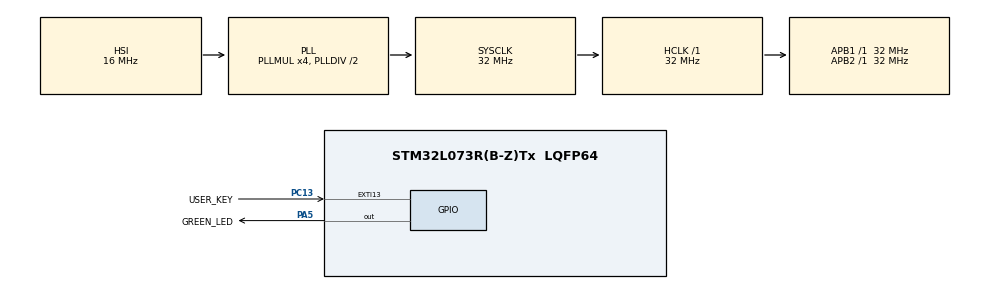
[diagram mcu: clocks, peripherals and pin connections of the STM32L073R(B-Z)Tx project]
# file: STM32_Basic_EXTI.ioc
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Mcu.Family=STM32L0
Mcu.Name=STM32L073R(B-Z)Tx
Mcu.Package=LQFP64
NVIC.EXTI4_15_IRQn=true\:1\:0\:true\:false\:true\:true
PA13.Mode=Serial_Wire
PA13.Signal=SYS_SWDIO
PA14.Mode=Serial_Wire
PA14.Signal=SYS_SWCLK
PA5.GPIO_Label=GREEN_LED
PA5.GPIO_Speed=GPIO_SPEED_FREQ_MEDIUM
PA5.Signal=GPIO_Output
PC13.GPIO_Label=USER_KEY
PC13.GPIO_ModeDefaultEXTI=GPIO_MODE_IT_FALLING
PC13.Signal=GPXTI13
ProjectManager.HeapSize=0x200
ProjectManager.StackSize=0x400
ProjectManager.TargetToolchain=TrueSTUDIO
RCC.AHBFreq_Value=32000000
RCC.APB1Freq_Value=32000000
RCC.APB1TimFreq_Value=32000000
RCC.APB2Freq_Value=32000000
RCC.APB2TimFreq_Value=32000000
RCC.HCLKFreq_Value=32000000
RCC.HSE_VALUE=8000000
RCC.HSI16_VALUE=16000000
RCC.HSI48_VALUE=48000000
RCC.HSI_VALUE=16000000
RCC.LSE_VALUE=32768
RCC.MSI_VALUE=2097000
RCC.PLLMUL=RCC_PLLMUL_4
RCC.SYSCLKFreq_VALUE=32000000
RCC.SYSCLKSource=RCC_SYSCLKSOURCE_PLLCLK
RCC.VCOOutputFreq_Value=64000000
board=custom

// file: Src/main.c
/* USER CODE BEGIN Header */
/**
  ******************************************************************************
  * @file           : main.c
  * @brief          : Main program body
  ******************************************************************************
  ** This notice applies to any and all portions of this file
  * that are not between comment pairs USER CODE BEGIN and
  * USER CODE END. Other portions of this file, whether
  * inserted by the user or by software development tools
  * are owned by their respective copyright owners.
  *
  * COPYRIGHT(c) 2019 STMicroelectronics
  *
  * Redistribution and use in source and binary forms, with or without modification,
  * are permitted provided that the following conditions are met:
  *   1. Redistributions of source code must retain the above copyright notice,
  *      this list of conditions and the following disclaimer.
  *   2. Redistributions in binary form must reproduce the above copyright notice,
  *      this list of conditions and the following disclaimer in the documentation
  *      and/or other materials provided with the distribution.
  *   3. Neither the name of STMicroelectronics nor the names of its contributors
  *      may be used to endorse or promote products derived from this software
  *      without specific prior written permission.
  *
  * THIS SOFTWARE IS PROVIDED BY THE COPYRIGHT HOLDERS AND CONTRIBUTORS "AS IS"
  * AND ANY EXPRESS OR IMPLIED WARRANTIES, INCLUDING, BUT NOT LIMITED TO, THE
  * IMPLIED WARRANTIES OF MERCHANTABILITY AND FITNESS FOR A PARTICULAR PURPOSE ARE
  * DISCLAIMED. IN NO EVENT SHALL THE COPYRIGHT HOLDER OR CONTRIBUTORS BE LIABLE
  * FOR ANY DIRECT, INDIRECT, INCIDENTAL, SPECIAL, EXEMPLARY, OR CONSEQUENTIAL
  * DAMAGES (INCLUDING, BUT NOT LIMITED TO, PROCUREMENT OF SUBSTITUTE GOODS OR
  * SERVICES; LOSS OF USE, DATA, OR PROFITS; OR BUSINESS INTERRUPTION) HOWEVER
  * CAUSED AND ON ANY THEORY OF LIABILITY, WHETHER IN CONTRACT, STRICT LIABILITY,
  * OR TORT (INCLUDING NEGLIGENCE OR OTHERWISE) ARISING IN ANY WAY OUT OF THE USE
  * OF THIS SOFTWARE, EVEN IF ADVISED OF THE POSSIBILITY OF SUCH DAMAGE.
  *
  ******************************************************************************
  */
/* USER CODE END Header */

#include "main.h"

void SystemClock_Config(void);
static void MX_GPIO_Init(void);

/* USER CODE BEGIN 0 */
void HAL_GPIO_EXTI_Callback(uint16_t GPIO_Pin)
{
  if(GPIO_Pin == USER_KEY_Pin)
  {
    HAL_GPIO_TogglePin(GREEN_LED_GPIO_Port, GREEN_LED_Pin);
    HAL_Delay(1000);
  }
}
/* USER CODE END 0 */

int main(void)
{

  /* MCU Configuration--------------------------------------------------------*/

  /* Reset of all peripherals, Initializes the Flash interface and the Systick. */
  HAL_Init();

  /* Configure the system clock */
  SystemClock_Config();

  /* Initialize all configured peripherals */
  MX_GPIO_Init();

  /* Infinite loop */
  while (1)
  {

  }
}

void SystemClock_Config(void)
{
  RCC_OscInitTypeDef RCC_OscInitStruct = {0};
  RCC_ClkInitTypeDef RCC_ClkInitStruct = {0};

  /**Configure the main internal regulator output voltage
  */
  __HAL_PWR_VOLTAGESCALING_CONFIG(PWR_REGULATOR_VOLTAGE_SCALE1);
  /**Initializes the CPU, AHB and APB busses clocks
  */
  RCC_OscInitStruct.OscillatorType = RCC_OSCILLATORTYPE_HSI;
  RCC_OscInitStruct.HSIState = RCC_HSI_ON;
  RCC_OscInitStruct.HSICalibrationValue = RCC_HSICALIBRATION_DEFAULT;
  RCC_OscInitStruct.PLL.PLLState = RCC_PLL_ON;
  RCC_OscInitStruct.PLL.PLLSource = RCC_PLLSOURCE_HSI;
  RCC_OscInitStruct.PLL.PLLMUL = RCC_PLLMUL_4;
  RCC_OscInitStruct.PLL.PLLDIV = RCC_PLLDIV_2;
  if (HAL_RCC_OscConfig(&RCC_OscInitStruct) != HAL_OK)
  {
    Error_Handler();
  }
  /**Initializes the CPU, AHB and APB busses clocks
  */
  RCC_ClkInitStruct.ClockType = RCC_CLOCKTYPE_HCLK|RCC_CLOCKTYPE_SYSCLK
                              |RCC_CLOCKTYPE_PCLK1|RCC_CLOCKTYPE_PCLK2;
  RCC_ClkInitStruct.SYSCLKSource = RCC_SYSCLKSOURCE_PLLCLK;
  RCC_ClkInitStruct.AHBCLKDivider = RCC_SYSCLK_DIV1;
  RCC_ClkInitStruct.APB1CLKDivider = RCC_HCLK_DIV1;
  RCC_ClkInitStruct.APB2CLKDivider = RCC_HCLK_DIV1;

  if (HAL_RCC_ClockConfig(&RCC_ClkInitStruct, FLASH_LATENCY_1) != HAL_OK)
  {
    Error_Handler();
  }
}

static void MX_GPIO_Init(void)
{
  GPIO_InitTypeDef GPIO_InitStruct = {0};

  /* GPIO Ports Clock Enable */
  __HAL_RCC_GPIOC_CLK_ENABLE();
  __HAL_RCC_GPIOA_CLK_ENABLE();

  /*Configure GPIO pin Output Level */
  HAL_GPIO_WritePin(GREEN_LED_GPIO_Port, GREEN_LED_Pin, GPIO_PIN_RESET);

  /*Configure GPIO pin : USER_KEY_Pin */
  GPIO_InitStruct.Pin = USER_KEY_Pin;
  GPIO_InitStruct.Mode = GPIO_MODE_IT_FALLING;
  GPIO_InitStruct.Pull = GPIO_NOPULL;
  HAL_GPIO_Init(USER_KEY_GPIO_Port, &GPIO_InitStruct);

  /*Configure GPIO pin : GREEN_LED_Pin */
  GPIO_InitStruct.Pin = GREEN_LED_Pin;
  GPIO_InitStruct.Mode = GPIO_MODE_OUTPUT_PP;
  GPIO_InitStruct.Pull = GPIO_NOPULL;
  GPIO_InitStruct.Speed = GPIO_SPEED_FREQ_MEDIUM;
  HAL_GPIO_Init(GREEN_LED_GPIO_Port, &GPIO_InitStruct);

  /* EXTI interrupt init*/
  HAL_NVIC_SetPriority(EXTI4_15_IRQn, 1, 0);
  HAL_NVIC_EnableIRQ(EXTI4_15_IRQn);

}

void Error_Handler(void)
{
}

/************************ (C) COPYRIGHT STMicroelectronics *****END OF FILE****/
